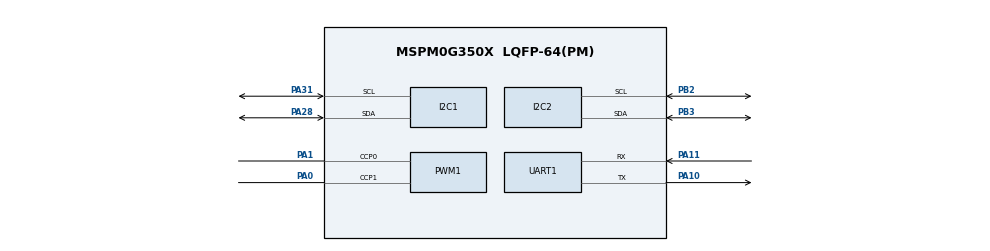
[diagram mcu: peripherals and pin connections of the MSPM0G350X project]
/**
 * @cliArgs --device "MSPM0G350X" --part "Default" --package "LQFP-64(PM)" --product "mspm0_sdk@2.10.00.04"
 * @versions {"tool":"1.26.2+4477"}
 */

/**
 * Import the modules used in this configuration.
 */
const ADC12  = scripting.addModule("/ti/driverlib/ADC12", {}, false);
const ADC121 = ADC12.addInstance();
const GPIO   = scripting.addModule("/ti/driverlib/GPIO", {}, false);
const GPIO1  = GPIO.addInstance();
const GPIO2  = GPIO.addInstance();
const GPIO3  = GPIO.addInstance();
const GPIO4  = GPIO.addInstance();
const GPIO5  = GPIO.addInstance();
const GPIO6  = GPIO.addInstance();
const GPIO7  = GPIO.addInstance();
const GPIO8  = GPIO.addInstance();
const GPIO9  = GPIO.addInstance();
const GPIO10 = GPIO.addInstance();
const GPIO11 = GPIO.addInstance();
const I2C    = scripting.addModule("/ti/driverlib/I2C", {}, false);
const I2C1   = I2C.addInstance();
const I2C2   = I2C.addInstance();
const PWM    = scripting.addModule("/ti/driverlib/PWM", {}, false);
const PWM1   = PWM.addInstance();
const SYSCTL = scripting.addModule("/ti/driverlib/SYSCTL");
const TIMER  = scripting.addModule("/ti/driverlib/TIMER", {}, false);
const TIMER1 = TIMER.addInstance();
const UART   = scripting.addModule("/ti/driverlib/UART", {}, false);
const UART1  = UART.addInstance();
const UART2  = UART.addInstance();

/**
 * Write custom configuration values to the imported modules.
 */
const divider7       = system.clockTree["PLL_PDIV"];
divider7.divideValue = 2;

const divider9       = system.clockTree["UDIV"];
divider9.divideValue = 2;

const multiplier2         = system.clockTree["PLL_QDIV"];
multiplier2.multiplyValue = 5;

const mux8       = system.clockTree["HSCLKMUX"];
mux8.inputSelect = "HSCLKMUX_SYSPLL2X";

const pinFunction4     = system.clockTree["HFXT"];
pinFunction4.inputFreq = 40;

ADC121.$name                             = "ADC12_0";
ADC121.sampClkDiv                        = "DL_ADC12_CLOCK_DIVIDE_8";
ADC121.repeatMode                        = true;
ADC121.configureDMA                      = true;
ADC121.adcMem0_name                      = "ADC_CH0";
ADC121.sampleTime0                       = "2us";
ADC121.enabledDMATriggers                = ["DL_ADC12_DMA_MEM0_RESULT_LOADED"];
ADC121.sampCnt                           = 1;
ADC121.peripheral.adcPin0.$assign        = "PA27";
ADC121.adcPin0Config.$name               = "ti_driverlib_gpio_GPIOPinGeneric8";
ADC121.DMA_CHANNEL.$name                 = "DMA_CH0";
ADC121.DMA_CHANNEL.configureTransferSize = true;
ADC121.DMA_CHANNEL.transferMode          = "FULL_CH_REPEAT_SINGLE";
ADC121.DMA_CHANNEL.srcLength             = "HALF_WORD";
ADC121.DMA_CHANNEL.dstLength             = "HALF_WORD";
ADC121.DMA_CHANNEL.transferSize          = 40;
ADC121.DMA_CHANNEL.addressMode           = "f2b";

const Board = scripting.addModule("/ti/driverlib/Board", {}, false);

GPIO1.$name                               = "GPIO_MPU6050";
GPIO1.associatedPins[0].direction         = "INPUT";
GPIO1.associatedPins[0].internalResistor  = "PULL_UP";
GPIO1.associatedPins[0].interruptEn       = true;
GPIO1.associatedPins[0].interruptPriority = "1";
GPIO1.associatedPins[0].polarity          = "FALL";
GPIO1.associatedPins[0].$name             = "PIN_MPU6050_INT";
GPIO1.associatedPins[0].assignedPort      = "PORTA";
GPIO1.associatedPins[0].assignedPin       = "25";

GPIO2.$name                               = "GPIO_EncoderA";
GPIO2.port                                = "PORTA";
GPIO2.associatedPins.create(2);
GPIO2.associatedPins[0].$name             = "PIN_0";
GPIO2.associatedPins[0].direction         = "INPUT";
GPIO2.associatedPins[0].interruptPriority = "2";
GPIO2.associatedPins[0].assignedPin       = "12";
GPIO2.associatedPins[0].interruptEn       = true;
GPIO2.associatedPins[0].polarity          = "RISE_FALL";
GPIO2.associatedPins[0].internalResistor  = "PULL_UP";
GPIO2.associatedPins[0].inputFilter       = "8_CYCLES";
GPIO2.associatedPins[1].$name             = "PIN_1";
GPIO2.associatedPins[1].direction         = "INPUT";
GPIO2.associatedPins[1].assignedPin       = "13";
GPIO2.associatedPins[1].interruptPriority = "2";
GPIO2.associatedPins[1].internalResistor  = "PULL_UP";

GPIO3.$name                              = "Sensor";
GPIO3.associatedPins.create(5);
GPIO3.associatedPins[0].$name            = "P1";
GPIO3.associatedPins[0].direction        = "INPUT";
GPIO3.associatedPins[0].internalResistor = "PULL_DOWN";
GPIO3.associatedPins[0].assignedPin      = "24";
GPIO3.associatedPins[0].assignedPort     = "PORTB";
GPIO3.associatedPins[1].$name            = "P2";
GPIO3.associatedPins[1].direction        = "INPUT";
GPIO3.associatedPins[1].assignedPort     = "PORTB";
GPIO3.associatedPins[1].assignedPin      = "18";
GPIO3.associatedPins[1].internalResistor = "PULL_DOWN";
GPIO3.associatedPins[2].$name            = "P3";
GPIO3.associatedPins[2].direction        = "INPUT";
GPIO3.associatedPins[2].assignedPort     = "PORTA";
GPIO3.associatedPins[2].assignedPin      = "14";
GPIO3.associatedPins[2].internalResistor = "PULL_DOWN";
GPIO3.associatedPins[3].$name            = "P4";
GPIO3.associatedPins[3].direction        = "INPUT";
GPIO3.associatedPins[3].assignedPort     = "PORTB";
GPIO3.associatedPins[3].assignedPin      = "19";
GPIO3.associatedPins[3].internalResistor = "PULL_DOWN";
GPIO3.associatedPins[4].$name            = "P5";
GPIO3.associatedPins[4].direction        = "INPUT";
GPIO3.associatedPins[4].assignedPort     = "PORTB";
GPIO3.associatedPins[4].assignedPin      = "20";
GPIO3.associatedPins[4].internalResistor = "PULL_DOWN";

GPIO4.$name                          = "DIR";
GPIO4.associatedPins.create(4);
GPIO4.associatedPins[0].$name        = "AIN1";
GPIO4.associatedPins[0].assignedPort = "PORTA";
GPIO4.associatedPins[0].assignedPin  = "17";
GPIO4.associatedPins[1].$name        = "AIN2";
GPIO4.associatedPins[1].assignedPort = "PORTA";
GPIO4.associatedPins[1].assignedPin  = "16";
GPIO4.associatedPins[2].$name        = "BIN1";
GPIO4.associatedPins[2].assignedPort = "PORTB";
GPIO4.associatedPins[2].assignedPin  = "1";
GPIO4.associatedPins[3].$name        = "BIN2";
GPIO4.associatedPins[3].assignedPort = "PORTB";
GPIO4.associatedPins[3].assignedPin  = "4";

GPIO5.$name                              = "KEY1";
GPIO5.associatedPins[0].direction        = "INPUT";
GPIO5.associatedPins[0].internalResistor = "PULL_UP";
GPIO5.associatedPins[0].assignedPort     = "PORTB";
GPIO5.associatedPins[0].assignedPin      = "0";
GPIO5.associatedPins[0].$name            = "KEY_1";

GPIO6.$name                              = "KEY2";
GPIO6.associatedPins[0].direction        = "INPUT";
GPIO6.associatedPins[0].internalResistor = "PULL_UP";
GPIO6.associatedPins[0].assignedPort     = "PORTA";
GPIO6.associatedPins[0].assignedPin      = "2";
GPIO6.associatedPins[0].$name            = "KEY_2";

GPIO7.$name                              = "KEY3";
GPIO7.associatedPins[0].direction        = "INPUT";
GPIO7.associatedPins[0].internalResistor = "PULL_UP";
GPIO7.associatedPins[0].$name            = "KEY_3";
GPIO7.associatedPins[0].assignedPort     = "PORTB";
GPIO7.associatedPins[0].assignedPin      = "16";

GPIO8.$name                               = "GPIO_EncoderB";
GPIO8.associatedPins.create(2);
GPIO8.associatedPins[0].$name             = "PIN_2";
GPIO8.associatedPins[0].direction         = "INPUT";
GPIO8.associatedPins[0].inputFilter       = "8_CYCLES";
GPIO8.associatedPins[0].assignedPort      = "PORTB";
GPIO8.associatedPins[0].assignedPin       = "22";
GPIO8.associatedPins[0].interruptEn       = true;
GPIO8.associatedPins[0].interruptPriority = "2";
GPIO8.associatedPins[0].polarity          = "RISE_FALL";
GPIO8.associatedPins[0].internalResistor  = "PULL_UP";
GPIO8.associatedPins[1].$name             = "PIN_3";
GPIO8.associatedPins[1].direction         = "INPUT";
GPIO8.associatedPins[1].assignedPort      = "PORTB";
GPIO8.associatedPins[1].assignedPin       = "23";
GPIO8.associatedPins[1].inputFilter       = "8_CYCLES";
GPIO8.associatedPins[1].internalResistor  = "PULL_UP";

GPIO9.$name                              = "LED";
GPIO9.port                               = "PORTB";
GPIO9.associatedPins.create(2);
GPIO9.associatedPins[0].internalResistor = "PULL_UP";
GPIO9.associatedPins[0].assignedPin      = "25";
GPIO9.associatedPins[0].$name            = "LED3";
GPIO9.associatedPins[1].$name            = "LED4";
GPIO9.associatedPins[1].assignedPin      = "26";
GPIO9.associatedPins[1].internalResistor = "PULL_UP";

GPIO10.$name                              = "BUZZER";
GPIO10.port                               = "PORTB";
GPIO10.associatedPins[0].assignedPin      = "13";
GPIO10.associatedPins[0].internalResistor = "PULL_DOWN";
GPIO10.associatedPins[0].$name            = "buzzer";

GPIO11.$name                          = "Gray_address";
GPIO11.associatedPins.create(3);
GPIO11.associatedPins[0].$name        = "PIN_4";
GPIO11.associatedPins[0].assignedPort = "PORTA";
GPIO11.associatedPins[0].assignedPin  = "26";
GPIO11.associatedPins[1].$name        = "PIN_5";
GPIO11.associatedPins[1].assignedPort = "PORTA";
GPIO11.associatedPins[1].assignedPin  = "7";
GPIO11.associatedPins[2].$name        = "PIN_6";
GPIO11.associatedPins[2].assignedPort = "PORTA";
GPIO11.associatedPins[2].assignedPin  = "18";

I2C1.$name                             = "I2C_OLED";
I2C1.basicEnableController             = true;
I2C1.basicControllerStandardBusSpeed   = "Fast";
I2C1.peripheral.sdaPin.$assign         = "PA28";
I2C1.peripheral.sclPin.$assign         = "PA31";
I2C1.sdaPinConfig.hideOutputInversion  = scripting.forceWrite(false);
I2C1.sdaPinConfig.onlyInternalResistor = scripting.forceWrite(false);
I2C1.sdaPinConfig.passedPeripheralType = scripting.forceWrite("Digital");
I2C1.sdaPinConfig.$name                = "ti_driverlib_gpio_GPIOPinGeneric6";
I2C1.sclPinConfig.hideOutputInversion  = scripting.forceWrite(false);
I2C1.sclPinConfig.onlyInternalResistor = scripting.forceWrite(false);
I2C1.sclPinConfig.passedPeripheralType = scripting.forceWrite("Digital");
I2C1.sclPinConfig.$name                = "ti_driverlib_gpio_GPIOPinGeneric7";

I2C2.$name                             = "I2C_MPU6050";
I2C2.basicEnableController             = true;
I2C2.basicControllerStandardBusSpeed   = "Fast";
I2C2.peripheral.$assign                = "I2C1";
I2C2.peripheral.sdaPin.$assign         = "PB3";
I2C2.peripheral.sclPin.$assign         = "PB2";
I2C2.sdaPinConfig.hideOutputInversion  = scripting.forceWrite(false);
I2C2.sdaPinConfig.onlyInternalResistor = scripting.forceWrite(false);
I2C2.sdaPinConfig.passedPeripheralType = scripting.forceWrite("Digital");
I2C2.sdaPinConfig.$name                = "ti_driverlib_gpio_GPIOPinGeneric0";
I2C2.sclPinConfig.hideOutputInversion  = scripting.forceWrite(false);
I2C2.sclPinConfig.onlyInternalResistor = scripting.forceWrite(false);
I2C2.sclPinConfig.passedPeripheralType = scripting.forceWrite("Digital");
I2C2.sclPinConfig.$name                = "ti_driverlib_gpio_GPIOPinGeneric1";

PWM1.$name                      = "PWM_0";
PWM1.timerStartTimer            = true;
PWM1.timerCount                 = 3200;
PWM1.pwmMode                    = "EDGE_ALIGN_UP";
PWM1.clockDivider               = 4;
PWM1.PWM_CHANNEL_0.$name        = "ti_driverlib_pwm_PWMTimerCC0";
PWM1.ccp0PinConfig.$name        = "ti_driverlib_gpio_GPIOPinGeneric4";
PWM1.peripheral.$assign         = "TIMG8";
PWM1.peripheral.ccp0Pin.$assign = "PA1";
PWM1.peripheral.ccp1Pin.$assign = "PA0";
PWM1.PWM_CHANNEL_1.$name        = "ti_driverlib_pwm_PWMTimerCC1";
PWM1.ccp1PinConfig.$name        = "ti_driverlib_gpio_GPIOPinGeneric5";

SYSCTL.forceDefaultClkConfig = true;
SYSCTL.clockTreeEn           = true;

TIMER1.$name              = "TIMER_xunji_pid";
TIMER1.timerClkPrescale   = 100;
TIMER1.timerStartTimer    = true;
TIMER1.interrupts         = ["ZERO"];
TIMER1.timerMode          = "PERIODIC";
TIMER1.timerPeriod        = "1 ms";
TIMER1.peripheral.$assign = "TIMG7";

UART1.$name                    = "UART_0";
UART1.targetBaudRate           = 115200;
UART1.peripheral.$assign       = "UART0";
UART1.peripheral.rxPin.$assign = "PA11";
UART1.peripheral.txPin.$assign = "PA10";
UART1.txPinConfig.$name        = "ti_driverlib_gpio_GPIOPinGeneric2";
UART1.rxPinConfig.$name        = "ti_driverlib_gpio_GPIOPinGeneric3";

UART2.targetBaudRate                   = 115200;
UART2.$name                            = "DCC101v1_2";
UART2.txPinConfig.direction            = scripting.forceWrite("OUTPUT");
UART2.txPinConfig.hideOutputInversion  = scripting.forceWrite(false);
UART2.txPinConfig.onlyInternalResistor = scripting.forceWrite(false);
UART2.txPinConfig.passedPeripheralType = scripting.forceWrite("Digital");
UART2.txPinConfig.$name                = "ti_driverlib_gpio_GPIOPinGeneric9";
UART2.rxPinConfig.hideOutputInversion  = scripting.forceWrite(false);
UART2.rxPinConfig.onlyInternalResistor = scripting.forceWrite(false);
UART2.rxPinConfig.passedPeripheralType = scripting.forceWrite("Digital");
UART2.rxPinConfig.$name                = "ti_driverlib_gpio_GPIOPinGeneric10";

/**
 * Pinmux solution for unlocked pins/peripherals. This ensures that minor changes to the automatic solver in a future
 * version of the tool will not impact the pinmux you originally saw.  These lines can be completely deleted in order to
 * re-solve from scratch.
 */
ADC121.peripheral.$suggestSolution             = "ADC0";
ADC121.DMA_CHANNEL.peripheral.$suggestSolution = "DMA_CH0";
Board.peripheral.$suggestSolution              = "DEBUGSS";
Board.peripheral.swclkPin.$suggestSolution     = "PA20";
Board.peripheral.swdioPin.$suggestSolution     = "PA19";
GPIO1.associatedPins[0].pin.$suggestSolution   = "PA25";
GPIO2.associatedPins[0].pin.$suggestSolution   = "PA12";
GPIO2.associatedPins[1].pin.$suggestSolution   = "PA13";
GPIO3.associatedPins[0].pin.$suggestSolution   = "PB24";
GPIO3.associatedPins[1].pin.$suggestSolution   = "PB18";
GPIO3.associatedPins[2].pin.$suggestSolution   = "PA14";
GPIO3.associatedPins[3].pin.$suggestSolution   = "PB19";
GPIO3.associatedPins[4].pin.$suggestSolution   = "PB20";
GPIO4.associatedPins[0].pin.$suggestSolution   = "PA17";
GPIO4.associatedPins[1].pin.$suggestSolution   = "PA16";
GPIO4.associatedPins[2].pin.$suggestSolution   = "PB1";
GPIO4.associatedPins[3].pin.$suggestSolution   = "PB4";
GPIO5.associatedPins[0].pin.$suggestSolution   = "PB0";
GPIO6.associatedPins[0].pin.$suggestSolution   = "PA2";
GPIO7.associatedPins[0].pin.$suggestSolution   = "PB16";
GPIO8.associatedPins[0].pin.$suggestSolution   = "PB22";
GPIO8.associatedPins[1].pin.$suggestSolution   = "PB23";
GPIO9.associatedPins[0].pin.$suggestSolution   = "PB25";
GPIO9.associatedPins[1].pin.$suggestSolution   = "PB26";
GPIO10.associatedPins[0].pin.$suggestSolution  = "PB13";
GPIO11.associatedPins[0].pin.$suggestSolution  = "PA26";
GPIO11.associatedPins[1].pin.$suggestSolution  = "PA7";
GPIO11.associatedPins[2].pin.$suggestSolution  = "PA18";
I2C1.peripheral.$suggestSolution               = "I2C0";
UART2.peripheral.$suggestSolution              = "UART1";
UART2.peripheral.rxPin.$suggestSolution        = "PA9";
UART2.peripheral.txPin.$suggestSolution        = "PA8";
